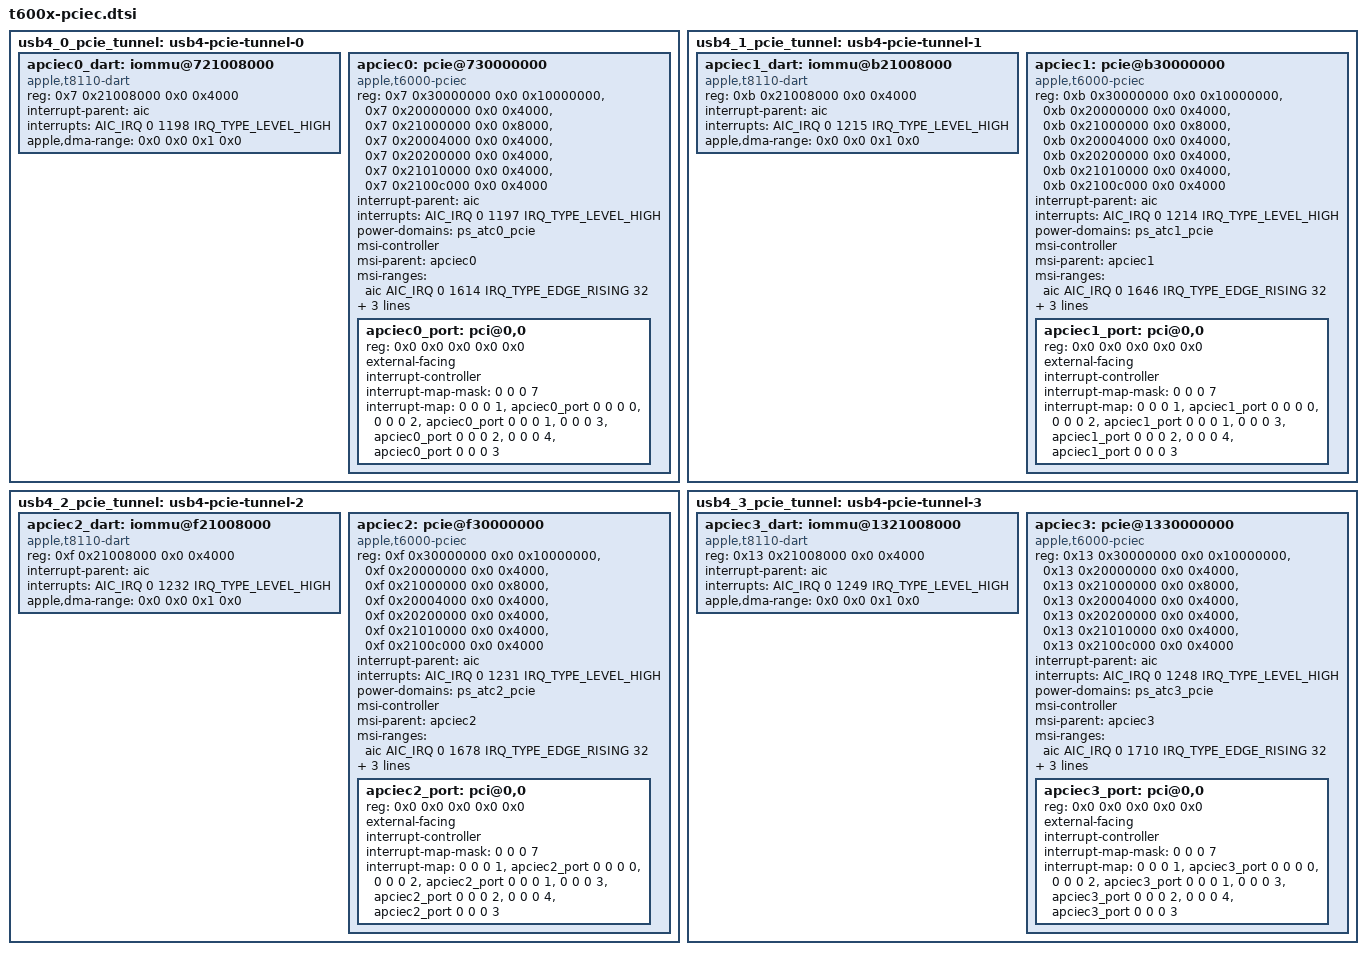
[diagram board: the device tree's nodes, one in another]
// SPDX-License-Identifier: GPL-2.0+ OR MIT
/*
 * PCIe-C root complexes used by USB4 tunnels on T6000/T6001.
 *
 * Copyright The Asahi Linux Contributors
 */

	usb4_0_pcie_tunnel: usb4-pcie-tunnel-0 {
		#address-cells = <2>;
		#size-cells = <2>;
		ranges;

		apciec0_dart: iommu@721008000 {
			compatible = "apple,t8110-dart";
			reg = <0x7 0x21008000 0x0 0x4000>;
			interrupt-parent = <&aic>;
			interrupts = <AIC_IRQ 0 1198 IRQ_TYPE_LEVEL_HIGH>;
			#iommu-cells = <1>;
			apple,dma-range = <0x0 0x0 0x1 0x0>;
#include "t600x-pciec-dart-tunables.dtsi"
		};

		apciec0: pcie@730000000 {
			compatible = "apple,t6000-pciec";
			device_type = "pci";

			reg = <0x7 0x30000000 0x0 0x10000000>,
				<0x7 0x20000000 0x0 0x4000>,
				<0x7 0x21000000 0x0 0x8000>,
				<0x7 0x20004000 0x0 0x4000>,
				<0x7 0x20200000 0x0 0x4000>,
				<0x7 0x21010000 0x0 0x4000>,
				<0x7 0x2100c000 0x0 0x4000>;
			reg-names = "config", "rc", "port0", "fabric",
				    "debug", "ltssm", "intr2axi";

			interrupt-parent = <&aic>;
			interrupts = <AIC_IRQ 0 1197 IRQ_TYPE_LEVEL_HIGH>;
			power-domains = <&ps_atc0_pcie>;

			msi-controller;
			msi-parent = <&apciec0>;
			msi-ranges = <&aic AIC_IRQ 0 1614 IRQ_TYPE_EDGE_RISING 32>;

			iommu-map = <0x0 &apciec0_dart 0x0 0x40>;
			iommu-map-mask = <0x3f>;

			bus-range = <0x0 0x7f>;
			#address-cells = <3>;
			#size-cells = <2>;
			ranges = <0x43000000 0x8 0x0
				  0x8 0x0 0x2 0x0>,
				 <0x02000000 0x0 0x00100000
				  0xa 0x00100000 0x0 0x3ff00000>,
				 <0x42000000 0x0 0x40000000
				  0xa 0x40000000 0x0 0x40000000>;

			apciec0_port: pci@0,0 {
				device_type = "pci";
				reg = <0x0 0x0 0x0 0x0 0x0>;
				external-facing;

				#address-cells = <3>;
				#size-cells = <2>;
				ranges;

				interrupt-controller;
				#interrupt-cells = <1>;
				interrupt-map-mask = <0 0 0 7>;
				interrupt-map = <0 0 0 1 &apciec0_port 0 0 0 0>,
						<0 0 0 2 &apciec0_port 0 0 0 1>,
						<0 0 0 3 &apciec0_port 0 0 0 2>,
						<0 0 0 4 &apciec0_port 0 0 0 3>;
			};
		};
	};

	usb4_1_pcie_tunnel: usb4-pcie-tunnel-1 {
		#address-cells = <2>;
		#size-cells = <2>;
		ranges;

		apciec1_dart: iommu@b21008000 {
			compatible = "apple,t8110-dart";
			reg = <0xb 0x21008000 0x0 0x4000>;
			interrupt-parent = <&aic>;
			interrupts = <AIC_IRQ 0 1215 IRQ_TYPE_LEVEL_HIGH>;
			#iommu-cells = <1>;
			apple,dma-range = <0x0 0x0 0x1 0x0>;
#include "t600x-pciec-dart-tunables.dtsi"
		};

		apciec1: pcie@b30000000 {
			compatible = "apple,t6000-pciec";
			device_type = "pci";

			reg = <0xb 0x30000000 0x0 0x10000000>,
				<0xb 0x20000000 0x0 0x4000>,
				<0xb 0x21000000 0x0 0x8000>,
				<0xb 0x20004000 0x0 0x4000>,
				<0xb 0x20200000 0x0 0x4000>,
				<0xb 0x21010000 0x0 0x4000>,
				<0xb 0x2100c000 0x0 0x4000>;
			reg-names = "config", "rc", "port0", "fabric",
				    "debug", "ltssm", "intr2axi";

			interrupt-parent = <&aic>;
			interrupts = <AIC_IRQ 0 1214 IRQ_TYPE_LEVEL_HIGH>;
			power-domains = <&ps_atc1_pcie>;

			msi-controller;
			msi-parent = <&apciec1>;
			msi-ranges = <&aic AIC_IRQ 0 1646 IRQ_TYPE_EDGE_RISING 32>;

			iommu-map = <0x0 &apciec1_dart 0x0 0x40>;
			iommu-map-mask = <0x3f>;

			bus-range = <0x0 0x7f>;
			#address-cells = <3>;
			#size-cells = <2>;
			ranges = <0x43000000 0xc 0x0
				  0xc 0x0 0x2 0x0>,
				 <0x02000000 0x0 0x00100000
				  0xe 0x00100000 0x0 0x3ff00000>,
				 <0x42000000 0x0 0x40000000
				  0xe 0x40000000 0x0 0x40000000>;

			apciec1_port: pci@0,0 {
				device_type = "pci";
				reg = <0x0 0x0 0x0 0x0 0x0>;
				external-facing;

				#address-cells = <3>;
				#size-cells = <2>;
				ranges;

				interrupt-controller;
				#interrupt-cells = <1>;
				interrupt-map-mask = <0 0 0 7>;
				interrupt-map = <0 0 0 1 &apciec1_port 0 0 0 0>,
						<0 0 0 2 &apciec1_port 0 0 0 1>,
						<0 0 0 3 &apciec1_port 0 0 0 2>,
						<0 0 0 4 &apciec1_port 0 0 0 3>;
			};
		};
	};

	usb4_2_pcie_tunnel: usb4-pcie-tunnel-2 {
		#address-cells = <2>;
		#size-cells = <2>;
		ranges;

		apciec2_dart: iommu@f21008000 {
			compatible = "apple,t8110-dart";
			reg = <0xf 0x21008000 0x0 0x4000>;
			interrupt-parent = <&aic>;
			interrupts = <AIC_IRQ 0 1232 IRQ_TYPE_LEVEL_HIGH>;
			#iommu-cells = <1>;
			apple,dma-range = <0x0 0x0 0x1 0x0>;
#include "t600x-pciec-dart-tunables.dtsi"
		};

		apciec2: pcie@f30000000 {
			compatible = "apple,t6000-pciec";
			device_type = "pci";

			reg = <0xf 0x30000000 0x0 0x10000000>,
				<0xf 0x20000000 0x0 0x4000>,
				<0xf 0x21000000 0x0 0x8000>,
				<0xf 0x20004000 0x0 0x4000>,
				<0xf 0x20200000 0x0 0x4000>,
				<0xf 0x21010000 0x0 0x4000>,
				<0xf 0x2100c000 0x0 0x4000>;
			reg-names = "config", "rc", "port0", "fabric",
				    "debug", "ltssm", "intr2axi";

			interrupt-parent = <&aic>;
			interrupts = <AIC_IRQ 0 1231 IRQ_TYPE_LEVEL_HIGH>;
			power-domains = <&ps_atc2_pcie>;

			msi-controller;
			msi-parent = <&apciec2>;
			msi-ranges = <&aic AIC_IRQ 0 1678 IRQ_TYPE_EDGE_RISING 32>;

			iommu-map = <0x0 &apciec2_dart 0x0 0x40>;
			iommu-map-mask = <0x3f>;

			bus-range = <0x0 0x7f>;
			#address-cells = <3>;
			#size-cells = <2>;
			ranges = <0x43000000 0x10 0x0
				  0x10 0x0 0x2 0x0>,
				 <0x02000000 0x0 0x00100000
				  0x12 0x00100000 0x0 0x3ff00000>,
				 <0x42000000 0x0 0x40000000
				  0x12 0x40000000 0x0 0x40000000>;

			apciec2_port: pci@0,0 {
				device_type = "pci";
				reg = <0x0 0x0 0x0 0x0 0x0>;
				external-facing;

				#address-cells = <3>;
				#size-cells = <2>;
				ranges;

				interrupt-controller;
				#interrupt-cells = <1>;
				interrupt-map-mask = <0 0 0 7>;
				interrupt-map = <0 0 0 1 &apciec2_port 0 0 0 0>,
						<0 0 0 2 &apciec2_port 0 0 0 1>,
						<0 0 0 3 &apciec2_port 0 0 0 2>,
						<0 0 0 4 &apciec2_port 0 0 0 3>;
			};
		};
	};

	usb4_3_pcie_tunnel: usb4-pcie-tunnel-3 {
		#address-cells = <2>;
		#size-cells = <2>;
		ranges;

		apciec3_dart: iommu@1321008000 {
			compatible = "apple,t8110-dart";
			reg = <0x13 0x21008000 0x0 0x4000>;
			interrupt-parent = <&aic>;
			interrupts = <AIC_IRQ 0 1249 IRQ_TYPE_LEVEL_HIGH>;
			#iommu-cells = <1>;
			apple,dma-range = <0x0 0x0 0x1 0x0>;
		};

		apciec3: pcie@1330000000 {
			compatible = "apple,t6000-pciec";
			device_type = "pci";

			reg = <0x13 0x30000000 0x0 0x10000000>,
				<0x13 0x20000000 0x0 0x4000>,
				<0x13 0x21000000 0x0 0x8000>,
				<0x13 0x20004000 0x0 0x4000>,
				<0x13 0x20200000 0x0 0x4000>,
				<0x13 0x21010000 0x0 0x4000>,
				<0x13 0x2100c000 0x0 0x4000>;
			reg-names = "config", "rc", "port0", "fabric",
				    "debug", "ltssm", "intr2axi";

			interrupt-parent = <&aic>;
			interrupts = <AIC_IRQ 0 1248 IRQ_TYPE_LEVEL_HIGH>;
			power-domains = <&ps_atc3_pcie>;

			msi-controller;
			msi-parent = <&apciec3>;
			msi-ranges = <&aic AIC_IRQ 0 1710 IRQ_TYPE_EDGE_RISING 32>;

			iommu-map = <0x0 &apciec3_dart 0x0 0x40>;
			iommu-map-mask = <0x3f>;

			bus-range = <0x0 0x7f>;
			#address-cells = <3>;
			#size-cells = <2>;
			ranges = <0x43000000 0x14 0x0
				  0x14 0x0 0x2 0x0>,
				 <0x02000000 0x0 0x00100000
				  0x16 0x00100000 0x0 0x3ff00000>,
				 <0x42000000 0x0 0x40000000
				  0x16 0x40000000 0x0 0x40000000>;

			apciec3_port: pci@0,0 {
				device_type = "pci";
				reg = <0x0 0x0 0x0 0x0 0x0>;
				external-facing;

				#address-cells = <3>;
				#size-cells = <2>;
				ranges;

				interrupt-controller;
				#interrupt-cells = <1>;
				interrupt-map-mask = <0 0 0 7>;
				interrupt-map = <0 0 0 1 &apciec3_port 0 0 0 0>,
						<0 0 0 2 &apciec3_port 0 0 0 1>,
						<0 0 0 3 &apciec3_port 0 0 0 2>,
						<0 0 0 4 &apciec3_port 0 0 0 3>;
			};
		};
	};
